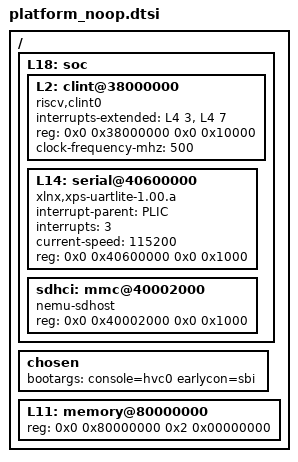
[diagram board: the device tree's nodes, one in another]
/dts-v1/;

/ {
	L18: soc {
		L2: clint@38000000 {
			compatible = "riscv,clint0";
			interrupts-extended = <&L4 3 &L4 7>;
			reg = <0x0 0x38000000 0x0 0x10000>;
			reg-names = "control";
			clock-frequency-mhz = <500>;
		};
		L14: serial@40600000 {
			compatible = "xlnx,xps-uartlite-1.00.a";
			interrupt-parent = <&PLIC>;
			interrupts = <3>;
			current-speed = <115200>;
			reg = <0x0 0x40600000 0x0 0x1000>;
			reg-names = "control";
		};
    sdhci: mmc@40002000 {
      compatible = "nemu-sdhost";
			reg = <0x0 0x40002000 0x0 0x1000>;
    };
	};
  chosen {
    bootargs = "console=hvc0 earlycon=sbi ";
  };
	L11: memory@80000000 {
		device_type = "memory";
		reg = <0x0 0x80000000 0x2 0x00000000>;
	};
};
